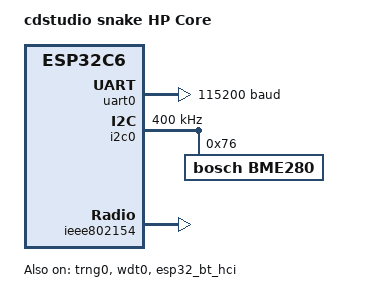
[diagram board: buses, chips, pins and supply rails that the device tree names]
/*
 * Copyright (c) 2026 cdstudio
 * SPDX-License-Identifier: Apache-2.0
 */

/dts-v1/;
#include <espressif/esp32c6/esp32c6_wroom_n8.dtsi>
#include "snake-pinctrl.dtsi"
#include <espressif/partitions_0x0_default.dtsi>

/ {
	model = "cdstudio snake HP Core";
	compatible = "espressif,esp32c6";

	chosen {
		zephyr,sram = &sramhp;
		zephyr,console = &uart0;
		zephyr,shell-uart = &uart0;
		zephyr,flash = &flash0;
		zephyr,code-partition = &slot0_partition;
		zephyr,ieee802154 = &ieee802154;
	};

	aliases {
		watchdog0 = &wdt0;
	};
};

&uart0 {
	status = "okay";
	current-speed = <115200>;
	pinctrl-0 = <&uart0_default>;
	pinctrl-names = "default";
};

&trng0 {
	status = "okay";
};

&i2c0 {
	status = "okay";
	clock-frequency = <I2C_BITRATE_FAST>;
	pinctrl-0 = <&i2c0_default>;
	pinctrl-names = "default";

	bme280: bme280@76 {
		compatible = "bosch,bme280";
		reg = <0x76>;
		label = "BME280";
	};
};

&gpio0 {
	status = "okay";
};

&wdt0 {
	status = "okay";
};

&ieee802154 {
	status = "okay";
};

&esp32_bt_hci {
	status = "okay";
};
